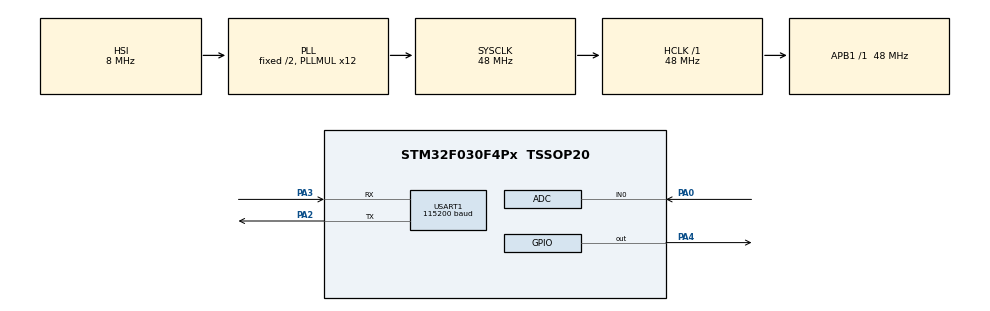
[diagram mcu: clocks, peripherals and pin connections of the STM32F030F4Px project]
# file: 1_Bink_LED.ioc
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Mcu.Family=STM32F0
Dma.ADC.0.Mode=DMA_CIRCULAR
USART1.BaudRate=115200
Dma.ADC.0.Priority=DMA_PRIORITY_LOW
RCC.SYSCLKSource=RCC_SYSCLKSOURCE_PLLCLK
ProjectManager.StackSize=0x400
Dma.ADC.0.PeriphDataAlignment=DMA_PDATAALIGN_HALFWORD
USART1.VirtualMode-Asynchronous=VM_ASYNC
PA3.Mode=Asynchronous
PA13.Signal=SYS_SWDIO
ProjectManager.TargetToolchain=STM32CubeIDE
Dma.ADC.0.PeriphInc=DMA_PINC_DISABLE
RCC.HCLKFreq_Value=48000000
RCC.AHBFreq_Value=48000000
PF0-OSC_IN.Mode=HSE-External-Oscillator
Dma.ADC.0.Direction=DMA_PERIPH_TO_MEMORY
ADC.SamplingTime=ADC_SAMPLETIME_71CYCLES_5
ADC.DMAContinuousRequests=ENABLE
board=custom
RCC.PLLMUL=RCC_PLL_MUL12
PA14.Mode=Serial_Wire
PA0.Mode=IN0
PA13.Mode=Serial_Wire
Mcu.Name=STM32F030F4Px
PA2.Signal=USART1_TX
PA0.Signal=ADC_IN0
Dma.ADC.0.MemInc=DMA_MINC_ENABLE
PA4.Signal=GPIO_Output
RCC.SYSCLKFreq_VALUE=48000000
Mcu.Package=TSSOP20
Dma.ADC.0.Instance=DMA1_Channel1
PA14.Signal=SYS_SWCLK
ProjectManager.HeapSize=0x200
Dma.ADC.0.MemDataAlignment=DMA_MDATAALIGN_HALFWORD
RCC.APB1TimFreq_Value=48000000
PA2.Mode=Asynchronous
NVIC.DMA1_Channel1_IRQn=true\:0\:0\:false\:false\:true\:false\:true
PF0-OSC_IN.Signal=RCC_OSC_IN
PF1-OSC_OUT.Mode=HSE-External-Oscillator
Dma.Request0=ADC
RCC.APB1Freq_Value=48000000
ADC.ContinuousConvMode=ENABLE
PF1-OSC_OUT.Signal=RCC_OSC_OUT
PA3.Signal=USART1_RX

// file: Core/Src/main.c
/* USER CODE BEGIN Header */
/**
  ******************************************************************************
  * @file           : main.c
  * @brief          : Main program body
  ******************************************************************************
  * @attention
  *
  * <h2><center>&copy; Copyright (c) 2021 STMicroelectronics.
  * All rights reserved.</center></h2>
  *
  * This software component is licensed by ST under BSD 3-Clause license,
  * the "License"; You may not use this file except in compliance with the
  * License. You may obtain a copy of the License at:
  *                        opensource.org/licenses/BSD-3-Clause
  *
  ******************************************************************************
  */
/* USER CODE END Header */
#include "main.h"

ADC_HandleTypeDef hadc;
DMA_HandleTypeDef hdma_adc;

UART_HandleTypeDef huart1;

void SystemClock_Config(void);
static void MX_GPIO_Init(void);
static void MX_DMA_Init(void);
static void MX_ADC_Init(void);
static void MX_USART1_UART_Init(void);

int main(void)
{

  /* MCU Configuration--------------------------------------------------------*/

  /* Reset of all peripherals, Initializes the Flash interface and the Systick. */
  HAL_Init();

  /* Configure the system clock */
  SystemClock_Config();

  /* Initialize all configured peripherals */
  MX_GPIO_Init();
  MX_DMA_Init();
  MX_ADC_Init();
  MX_USART1_UART_Init();

  /* Infinite loop */
  while (1)
  {

    /* USER CODE BEGIN 3 */
	  HAL_GPIO_TogglePin(GPIOA, GPIO_PIN_4);
	  HAL_Delay(200);
  }
  /* USER CODE END 3 */
}

void SystemClock_Config(void)
{
  RCC_OscInitTypeDef RCC_OscInitStruct = {0};
  RCC_ClkInitTypeDef RCC_ClkInitStruct = {0};
  RCC_PeriphCLKInitTypeDef PeriphClkInit = {0};

  /** Initializes the RCC Oscillators according to the specified parameters
  * in the RCC_OscInitTypeDef structure.
  */
  RCC_OscInitStruct.OscillatorType = RCC_OSCILLATORTYPE_HSI|RCC_OSCILLATORTYPE_HSI14;
  RCC_OscInitStruct.HSIState = RCC_HSI_ON;
  RCC_OscInitStruct.HSI14State = RCC_HSI14_ON;
  RCC_OscInitStruct.HSICalibrationValue = RCC_HSICALIBRATION_DEFAULT;
  RCC_OscInitStruct.HSI14CalibrationValue = 16;
  RCC_OscInitStruct.PLL.PLLState = RCC_PLL_ON;
  RCC_OscInitStruct.PLL.PLLSource = RCC_PLLSOURCE_HSI;
  RCC_OscInitStruct.PLL.PLLMUL = RCC_PLL_MUL12;
  RCC_OscInitStruct.PLL.PREDIV = RCC_PREDIV_DIV1;
  if (HAL_RCC_OscConfig(&RCC_OscInitStruct) != HAL_OK)
  {
    Error_Handler();
  }
  /** Initializes the CPU, AHB and APB buses clocks
  */
  RCC_ClkInitStruct.ClockType = RCC_CLOCKTYPE_HCLK|RCC_CLOCKTYPE_SYSCLK
                              |RCC_CLOCKTYPE_PCLK1;
  RCC_ClkInitStruct.SYSCLKSource = RCC_SYSCLKSOURCE_PLLCLK;
  RCC_ClkInitStruct.AHBCLKDivider = RCC_SYSCLK_DIV1;
  RCC_ClkInitStruct.APB1CLKDivider = RCC_HCLK_DIV1;

  if (HAL_RCC_ClockConfig(&RCC_ClkInitStruct, FLASH_LATENCY_1) != HAL_OK)
  {
    Error_Handler();
  }
  PeriphClkInit.PeriphClockSelection = RCC_PERIPHCLK_USART1;
  PeriphClkInit.Usart1ClockSelection = RCC_USART1CLKSOURCE_PCLK1;
  if (HAL_RCCEx_PeriphCLKConfig(&PeriphClkInit) != HAL_OK)
  {
    Error_Handler();
  }
}

static void MX_ADC_Init(void)
{

  ADC_ChannelConfTypeDef sConfig = {0};

  /** Configure the global features of the ADC (Clock, Resolution, Data Alignment and number of conversion)
  */
  hadc.Instance = ADC1;
  hadc.Init.ClockPrescaler = ADC_CLOCK_ASYNC_DIV1;
  hadc.Init.Resolution = ADC_RESOLUTION_12B;
  hadc.Init.DataAlign = ADC_DATAALIGN_RIGHT;
  hadc.Init.ScanConvMode = ADC_SCAN_DIRECTION_FORWARD;
  hadc.Init.EOCSelection = ADC_EOC_SINGLE_CONV;
  hadc.Init.LowPowerAutoWait = DISABLE;
  hadc.Init.LowPowerAutoPowerOff = DISABLE;
  hadc.Init.ContinuousConvMode = ENABLE;
  hadc.Init.DiscontinuousConvMode = DISABLE;
  hadc.Init.ExternalTrigConv = ADC_SOFTWARE_START;
  hadc.Init.ExternalTrigConvEdge = ADC_EXTERNALTRIGCONVEDGE_NONE;
  hadc.Init.DMAContinuousRequests = ENABLE;
  hadc.Init.Overrun = ADC_OVR_DATA_PRESERVED;
  if (HAL_ADC_Init(&hadc) != HAL_OK)
  {
    Error_Handler();
  }
  /** Configure for the selected ADC regular channel to be converted.
  */
  sConfig.Channel = ADC_CHANNEL_0;
  sConfig.Rank = ADC_RANK_CHANNEL_NUMBER;
  sConfig.SamplingTime = ADC_SAMPLETIME_71CYCLES_5;
  if (HAL_ADC_ConfigChannel(&hadc, &sConfig) != HAL_OK)
  {
    Error_Handler();
  }

}

static void MX_USART1_UART_Init(void)
{

  huart1.Instance = USART1;
  huart1.Init.BaudRate = 115200;
  huart1.Init.WordLength = UART_WORDLENGTH_8B;
  huart1.Init.StopBits = UART_STOPBITS_1;
  huart1.Init.Parity = UART_PARITY_NONE;
  huart1.Init.Mode = UART_MODE_TX_RX;
  huart1.Init.HwFlowCtl = UART_HWCONTROL_NONE;
  huart1.Init.OverSampling = UART_OVERSAMPLING_16;
  huart1.Init.OneBitSampling = UART_ONE_BIT_SAMPLE_DISABLE;
  huart1.AdvancedInit.AdvFeatureInit = UART_ADVFEATURE_NO_INIT;
  if (HAL_UART_Init(&huart1) != HAL_OK)
  {
    Error_Handler();
  }

}

static void MX_DMA_Init(void)
{

  /* DMA controller clock enable */
  __HAL_RCC_DMA1_CLK_ENABLE();

  /* DMA interrupt init */
  /* DMA1_Channel1_IRQn interrupt configuration */
  HAL_NVIC_SetPriority(DMA1_Channel1_IRQn, 0, 0);
  HAL_NVIC_EnableIRQ(DMA1_Channel1_IRQn);

}

static void MX_GPIO_Init(void)
{
  GPIO_InitTypeDef GPIO_InitStruct = {0};

  /* GPIO Ports Clock Enable */
  __HAL_RCC_GPIOF_CLK_ENABLE();
  __HAL_RCC_GPIOA_CLK_ENABLE();

  /*Configure GPIO pin Output Level */
  HAL_GPIO_WritePin(GPIOA, GPIO_PIN_4, GPIO_PIN_RESET);

  /*Configure GPIO pin : PA4 */
  GPIO_InitStruct.Pin = GPIO_PIN_4;
  GPIO_InitStruct.Mode = GPIO_MODE_OUTPUT_PP;
  GPIO_InitStruct.Pull = GPIO_NOPULL;
  GPIO_InitStruct.Speed = GPIO_SPEED_FREQ_LOW;
  HAL_GPIO_Init(GPIOA, &GPIO_InitStruct);

}

void Error_Handler(void)
{
  __disable_irq();
  while (1)
  {
  }
}

/************************ (C) COPYRIGHT STMicroelectronics *****END OF FILE****/
